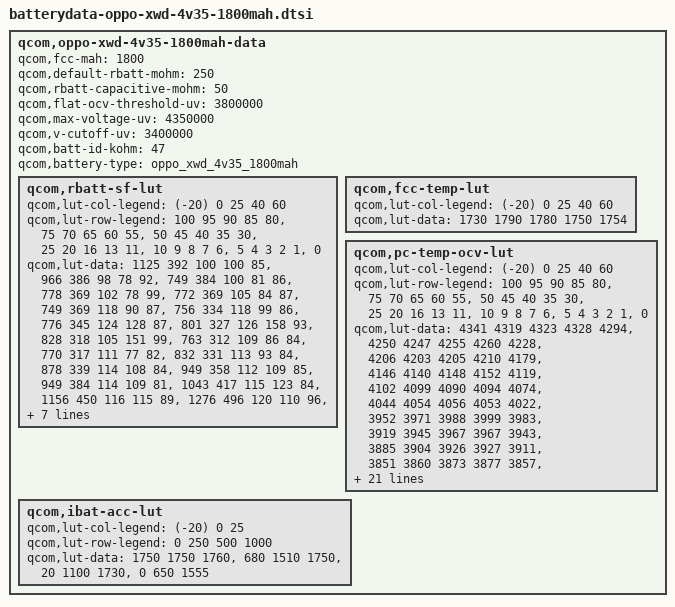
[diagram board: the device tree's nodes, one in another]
/* Copyright (c) 2013, The Linux Foundation. All rights reserved.
 *
 * This program is free software; you can redistribute it and/or modify
 * it under the terms of the GNU General Public License version 2 and
 * only version 2 as published by the Free Software Foundation.
 *
 * This program is distributed in the hope that it will be useful,
 * but WITHOUT ANY WARRANTY; without even the implied warranty of
 * MERCHANTABILITY or FITNESS FOR A PARTICULAR PURPOSE.  See the
 * GNU General Public License for more details.
 */

qcom,oppo-xwd-4v35-1800mah-data {
	qcom,fcc-mah = <1800>;
	qcom,default-rbatt-mohm = <250>;
	qcom,rbatt-capacitive-mohm = <50>;
	qcom,flat-ocv-threshold-uv = <3800000>;
	qcom,max-voltage-uv = <4350000>;
	qcom,v-cutoff-uv = <3400000>;
	//qcom,chg-term-ua = <100000>;
	qcom,batt-id-kohm = <47>;
	qcom,battery-type = "oppo_xwd_4v35_1800mah";

	qcom,rbatt-sf-lut {
		qcom,lut-col-legend = <(-20) 0 25 40 60>;
		qcom,lut-row-legend = <100 95 90 85 80>,
				<75 70 65 60 55>,
				<50 45 40 35 30>,
				<25 20 16 13 11>,
				<10 9 8 7 6>,
				<5 4 3 2 1>,
				<0>;
		qcom,lut-data = <1125 392 100 100 85>,
			   	<966 386 98 78 92 >,
			   	<749 384 100 81 86>,
			   	<778 369 102 78 99>,
			   	<772 369 105 84 87>,
			   	<749 369 118 90 87>,
			   	<756 334 118 99 86>,
			   	<776 345 124 128 87>,
			   	<801 327 126 158 93>,
			   	<828 318 105 151 99>,
			   	<763 312 109 86 84>,
			   	<770 317 111 77 82>,
			   	<832 331 113 93 84>,
			   	<878 339 114 108 84>,
			   	<949 358 112 109 85>,
			   	<949 384 114 109 81>,
			   	<1043 417 115 123 84>,
			   	<1156 450 116 115 89>,
			   	<1276 496 120 110 96>,
			   	<1356 513 116 103 92>,
			   	<1396 532 113 96 103>,
			   	<1436 555 113 94 101>,
			   	<1450 581 115 99 107>,
			   	<1500 611 121 99 106>,
			   	<1530 646 121 101 109>,
			   	<1580 684 119 99 125>,	
			   	<1600 716 123 93 134>,
			   	<1700 754 132 103 145>,
			  	<2000 813 150 117 177>,
			   	<5000 996 796 413 796>,
			   	<135251 124940 59087 49820 29672>;
	};

	qcom,fcc-temp-lut {
		qcom,lut-col-legend = <(-20) 0 25 40 60>;
		qcom,lut-data = <1730 1790 1780 1750 1754>;
	};
				
	qcom,pc-temp-ocv-lut {
		qcom,lut-col-legend = <(-20) 0 25 40 60>;
		qcom,lut-row-legend = <100 95 90 85 80>,
				<75 70 65 60 55>,
				<50 45 40 35 30>,
				<25 20 16 13 11>,
				<10 9 8 7 6>,
				<5 4 3 2 1>,
				<0>;
		qcom,lut-data = <4341 4319  4323   4328  4294>,
			   	<4250  4247  4255   4260   4228>,
			   	<4206  4203  4205   4210   4179>,
			   	<4146  4140  4148   4152   4119>,
			   	<4102  4099  4090   4094   4074>,
			   	<4044  4054  4056   4053   4022>,
			   	<3952  3971  3988   3999   3983>,
			   	<3919  3945  3967   3967   3943>,
			   	<3885  3904  3926   3927   3911>,
			   	<3851  3860  3873   3877   3857>,
			   	<3831  3830  3840   3843   3830>,
			   	<3809  3808  3816   3816   3807>,
			   	<3796  3793  3797   3799   3789>,
			   	<3790  3783  3787   3784   3777>,
			   	<3780  3777  3775   3772   3751>,
			   	<3772  3773  3766   3757   3735>,
			   	<3752  3758  3748   3741   3712>,
			   	<3733  3727  3720   3711   3675>,
			   	<3724  3703  3694   3685   3669>,
			   	<3716  3699  3690   3683   3669>,
			   	<3713  3697  3690   3681   3668>,
			  	<3711  3693  3690   3682   3667>,
			  	<3703  3691  3686   3682   3662>,
			   	<3689  3689  3684   3680   3641>,
			   	<3689  3689  3682   3674   3596>,
			   	<3679  3679  3668   3653   3550>,
			   	<3648  3648  3621   3599   3535>,
			   	<3583  3583  3551   3530   3450>,
			   	<3494  3494  3450   3421   3321>,
			   	<3213  3213  3256   3213   3250>,
				<3000  3000  3000   3000   3000>;
	};

	qcom,ibat-acc-lut {
		qcom,lut-col-legend = <(-20) 0 25>;
		qcom,lut-row-legend = <0 250 500 1000>;
		qcom,lut-data = <1750 1750 1760>,
				<680 1510 1750>,
				<20 1100 1730>,
				<0 650 1555>;
	};

};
